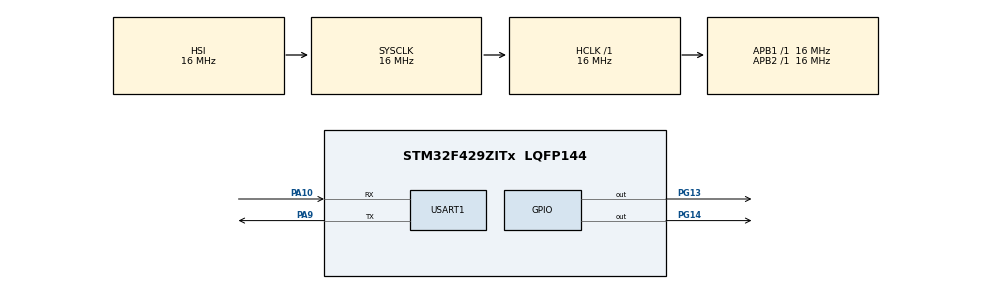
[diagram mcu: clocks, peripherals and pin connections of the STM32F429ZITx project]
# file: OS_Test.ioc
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FREERTOS.Tasks01=defaultTask,0,128,StartDefaultTask,Default,NULL,Dynamic,NULL,NULL
Mcu.Family=STM32F4
Mcu.Name=STM32F429ZITx
Mcu.Package=LQFP144
NVIC.PriorityGroup=NVIC_PRIORITYGROUP_4
PA10.Mode=Asynchronous
PA10.Signal=USART1_RX
PA9.Mode=Asynchronous
PA9.Signal=USART1_TX
PG13.Signal=GPIO_Output
PG14.Signal=GPIO_Output
ProjectManager.HeapSize=0x200
ProjectManager.StackSize=0x400
ProjectManager.TargetToolchain=STM32CubeIDE
RCC.AHBFreq_Value=16000000
RCC.APB1Freq_Value=16000000
RCC.APB2Freq_Value=16000000
RCC.CortexFreq_Value=16000000
RCC.HSE_VALUE=25000000
RCC.HSI_VALUE=16000000
RCC.LSE_VALUE=32768
RCC.SYSCLKFreq_VALUE=16000000
RCC.VCOOutputFreq_Value=192000000
USART1.VirtualMode=VM_ASYNC
VP_FREERTOS_VS_CMSIS_V1.Mode=CMSIS_V1
VP_RTC_VS_RTC_Activate.Mode=RTC_Enabled
board=custom

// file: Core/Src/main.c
/* USER CODE BEGIN Header */
/**
 ******************************************************************************
 * @file           : main.c
 * @brief          : Main program body
 ******************************************************************************
 * @attention
 *
 * Copyright (c) 2022 STMicroelectronics.
 * All rights reserved.
 *
 * This software is licensed under terms that can be found in the LICENSE file
 * in the root directory of this software component.
 * If no LICENSE file comes with this software, it is provided AS-IS.
 *
 ******************************************************************************
 */
/* USER CODE END Header */
#include "main.h"
#include "cmsis_os.h"

RTC_HandleTypeDef hrtc;

UART_HandleTypeDef huart1;

osThreadId defaultTaskHandle;

void SystemClock_Config(void);
static void MX_GPIO_Init(void);
static void MX_USART1_UART_Init(void);
static void MX_RTC_Init(void);
void StartDefaultTask(void const *argument);

/* USER CODE BEGIN 0 */
void LED_Test(void *pvparameters) {

	char temp2[] = "Main Task\r\n";
	for (;;) {
		HAL_UART_Transmit(&huart1, (uint8_t*) temp2, strlen(temp2), 10);
		//HAL_GPIO_WritePin(GPIOG, GPIO_PIN_14, GPIO_PIN_RESET);
		vTaskDelay(500 / portTICK_RATE_MS);
		//HAL_GPIO_WritePin(GPIOG, GPIO_PIN_14, GPIO_PIN_SET);
		//vTaskDelay(xDelay);
		// Write Back Up Register 1 Data
		//HAL_PWR_EnableBkUpAccess();
		//Writes a data in a RTC Backup data Register 1
		//HAL_RTCEx_BKUPWrite(&hrtc, RTC_BKP_DR1, 0xBEBE);
		//HAL_PWR_DisableBkUpAccess();
	}
}

void OTA_TASK(void *pvparameters) {
	TickType_t xDelay = 250 / portTICK_RATE_MS;
	char temp[] = "OTA Task\r\n";
	for (;;) {
		taskENTER_CRITICAL();
		HAL_UART_Transmit(&huart1, (uint8_t*) temp, strlen(temp), 10);
		taskEXIT_CRITICAL();

	}
}

/* USER CODE END 0 */

int main(void) {

	/* MCU Configuration--------------------------------------------------------*/

	/* Reset of all peripherals, Initializes the Flash interface and the Systick. */
	HAL_Init();

	/* Configure the system clock */
	SystemClock_Config();

	/* Initialize all configured peripherals */
	MX_GPIO_Init();
	MX_USART1_UART_Init();
	MX_RTC_Init();
	xTaskCreate(OTA_TASK, (const char* const ) "ota task", 240, 0, 1, NULL);
	xTaskCreate(LED_Test, (const char* const ) "main task",240, 0, 2, NULL);

	/* Create the thread(s) */
	/* definition and creation of defaultTask */
	//osThreadDef(defaultTask, StartDefaultTask, osPriorityNormal, 0, 128);
	//defaultTaskHandle = osThreadCreate(osThread(defaultTask), NULL);

	/* Start scheduler */
	osKernelStart();

	/* We should never get here as control is now taken by the scheduler */
	/* Infinite loop */
	while (1) {

	}
}

void SystemClock_Config(void) {
	RCC_OscInitTypeDef RCC_OscInitStruct = { 0 };
	RCC_ClkInitTypeDef RCC_ClkInitStruct = { 0 };

	/** Configure the main internal regulator output voltage
	 */
	__HAL_RCC_PWR_CLK_ENABLE();
	__HAL_PWR_VOLTAGESCALING_CONFIG(PWR_REGULATOR_VOLTAGE_SCALE3);

	/** Initializes the RCC Oscillators according to the specified parameters
	 * in the RCC_OscInitTypeDef structure.
	 */
	RCC_OscInitStruct.OscillatorType = RCC_OSCILLATORTYPE_HSI
			| RCC_OSCILLATORTYPE_LSI;
	RCC_OscInitStruct.HSIState = RCC_HSI_ON;
	RCC_OscInitStruct.HSICalibrationValue = RCC_HSICALIBRATION_DEFAULT;
	RCC_OscInitStruct.LSIState = RCC_LSI_ON;
	RCC_OscInitStruct.PLL.PLLState = RCC_PLL_NONE;
	if (HAL_RCC_OscConfig(&RCC_OscInitStruct) != HAL_OK) {
		Error_Handler();
	}

	/** Initializes the CPU, AHB and APB buses clocks
	 */
	RCC_ClkInitStruct.ClockType = RCC_CLOCKTYPE_HCLK | RCC_CLOCKTYPE_SYSCLK
			| RCC_CLOCKTYPE_PCLK1 | RCC_CLOCKTYPE_PCLK2;
	RCC_ClkInitStruct.SYSCLKSource = RCC_SYSCLKSOURCE_HSI;
	RCC_ClkInitStruct.AHBCLKDivider = RCC_SYSCLK_DIV1;
	RCC_ClkInitStruct.APB1CLKDivider = RCC_HCLK_DIV1;
	RCC_ClkInitStruct.APB2CLKDivider = RCC_HCLK_DIV1;

	if (HAL_RCC_ClockConfig(&RCC_ClkInitStruct, FLASH_LATENCY_0) != HAL_OK) {
		Error_Handler();
	}
}

static void MX_RTC_Init(void) {

	/** Initialize RTC Only
	 */
	hrtc.Instance = RTC;
	hrtc.Init.HourFormat = RTC_HOURFORMAT_24;
	hrtc.Init.AsynchPrediv = 127;
	hrtc.Init.SynchPrediv = 255;
	hrtc.Init.OutPut = RTC_OUTPUT_DISABLE;
	hrtc.Init.OutPutPolarity = RTC_OUTPUT_POLARITY_HIGH;
	hrtc.Init.OutPutType = RTC_OUTPUT_TYPE_OPENDRAIN;
	if (HAL_RTC_Init(&hrtc) != HAL_OK) {
		Error_Handler();
	}

}

static void MX_USART1_UART_Init(void) {

	huart1.Instance = USART1;
	huart1.Init.BaudRate = 115200;
	huart1.Init.WordLength = UART_WORDLENGTH_8B;
	huart1.Init.StopBits = UART_STOPBITS_1;
	huart1.Init.Parity = UART_PARITY_NONE;
	huart1.Init.Mode = UART_MODE_TX_RX;
	huart1.Init.HwFlowCtl = UART_HWCONTROL_NONE;
	huart1.Init.OverSampling = UART_OVERSAMPLING_16;
	if (HAL_UART_Init(&huart1) != HAL_OK) {
		Error_Handler();
	}

}

static void MX_GPIO_Init(void) {
	GPIO_InitTypeDef GPIO_InitStruct = { 0 };

	/* GPIO Ports Clock Enable */
	__HAL_RCC_GPIOA_CLK_ENABLE();
	__HAL_RCC_GPIOG_CLK_ENABLE();

	/*Configure GPIO pin Output Level */
	HAL_GPIO_WritePin(GPIOG, GPIO_PIN_13 | GPIO_PIN_14, GPIO_PIN_RESET);

	/*Configure GPIO pins : PG13 PG14 */
	GPIO_InitStruct.Pin = GPIO_PIN_13 | GPIO_PIN_14;
	GPIO_InitStruct.Mode = GPIO_MODE_OUTPUT_PP;
	GPIO_InitStruct.Pull = GPIO_NOPULL;
	GPIO_InitStruct.Speed = GPIO_SPEED_FREQ_LOW;
	HAL_GPIO_Init(GPIOG, &GPIO_InitStruct);

}

void StartDefaultTask(void const *argument) {
	for (;;) {
		osDelay(1);
	}
}

void Error_Handler(void) {
	__disable_irq();
	while (1) {
	}
}
